# FSS_FSAS_0_FSS_FSAS_GENREGS_0FC10000h register map
Vendor: Texas Instruments
Peripheral module from a debugger description file (folder am62D).
Registers are 32-bit, access not given, reset 0x0 unless marked. A register's access mark holds for its fields unless they carry their own. Offsets are as the file gives them; lines under a group give offsets from that group; [hi:lo] are bit positions; {n}, {i} and the like mark numbered series; 'fields as' and 'values as' point back to an identical list; <NAME> marks a mode.

## fss_fsas_genregs
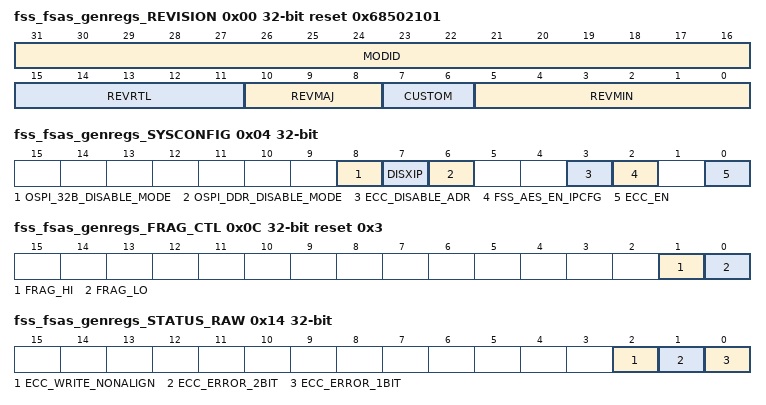
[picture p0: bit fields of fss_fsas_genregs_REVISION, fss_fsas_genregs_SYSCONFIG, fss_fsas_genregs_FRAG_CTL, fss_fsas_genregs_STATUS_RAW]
0x00 fss_fsas_genregs_REVISION ro reset 0x68502101 — IP Revision Identifier (X.Y.R) Used by software to track features, bugs, and compatibility
  [31:16] MODID — Module ID field Reset Source: vbus_mod_g_rst_n
  [15:11] REVRTL — RTL revision. Will vary depending on release. Reset Source: vbus_mod_g_rst_n
  [10:8] REVMAJ — Major revision Reset Source: vbus_mod_g_rst_n
  [7:6] CUSTOM — Custom Reset Source: vbus_mod_g_rst_n
  [5:0] REVMIN — Minor revision Reset Source: vbus_mod_g_rst_n
0x04 fss_fsas_genregs_SYSCONFIG access per field — Controls various parameters of the cotroller state.
  [8] OSPI_32B_DISABLE_MODE rw — 0 OSPI 32bit mode enabled. 1 OSPI 32bit mode disabled Reset Source: vbus_mod_g_rst_n
  [7] DISXIP rw — 0 XIP Prefetch Enabled. 1 XIP prefetch disabled Reset Source: vbus_mod_g_rst_n
  [6] OSPI_DDR_DISABLE_MODE rw — 0 OSPI DDR mode enabled. 1 OSPI DDR mode disabled Reset Source: vbus_mod_g_rst_n
  [3] ECC_DISABLE_ADR rw — 0 Block address within ECC calculation, 1 Block address not within ECC calculation Reset Source: vbus_mod_g_rst_n
  [2] FSS_AES_EN_IPCFG ro — 1 select security, 0 disable security Reset Source: vbus_mod_g_rst_n
  [0] ECC_EN rw — 0 ECC disabled. 1 ECC enabled Reset Source: vbus_mod_g_rst_n
0x08 fss_fsas_genregs_FRAG_ADR rw — This FRAG_ADR is the address of a request that frag_hi or frag_lo boundary occurs
  [31:0] FRAG_ADDR — This address is used to determine the boundary of frag_hi and flag_lo Reset Source: vbus_mod_g_rst_n
0x0C fss_fsas_genregs_FRAG_CTL rw reset 0x3 — The FRAG_CTL determins which frag region is fragmented
  [1] FRAG_HI — When set any address greater than or equal to frag_addr will be fragmented to 16 bits Reset Source: vbus_mod_g_rst_n
  [0] FRAG_LO — When set any address less than frag_addr will be fragmented to 16 bits Reset Source: vbus_mod_g_rst_n
0x10 fss_fsas_genregs_IRQ reset not defined
0x10 fss_fsas_genregs_EOI rw — The End of Interrupt (EOI) MISC Register allows the CPU to acknowledge completion of an interrupt by writing to the EOI for MISC interrupt sources. An eoi_write signal will be generated and another interrupt will be triggered if interrupt sources remain. This register will be reset one cycle after it has been written to.
  [0] EOI_VECTOR — Write with bit position of targeted interrupt. (E.g. Ext FSS ECC is bit 0). Upon write, level interrupt will clear and if un-serviced will issue another pulse interrupt Reset Source: vbus_mod_g_rst_n
0x14 fss_fsas_genregs_STATUS_RAW — The IRQ_STATUS_RAW register allows the interrupt sources to be manually set when writing a 1 to a specific bit. Write 0: No action Write 1: Set event Read 0: No event pending Read 1: Event pending
  [2] ECC_WRITE_NONALIGN — Write is not aligned to 32B boundary or not a multiple of 32B Reset Source: vbus_mod_g_rst_n (access R/W1TS)
  [1] ECC_ERROR_2BIT — ECC error on 2 bits. Not correctable Reset Source: vbus_mod_g_rst_n (access R/W1TS)
  [0] ECC_ERROR_1BIT — ECC error on 1 bits. correctable Reset Source: vbus_mod_g_rst_n (access R/W1TS)
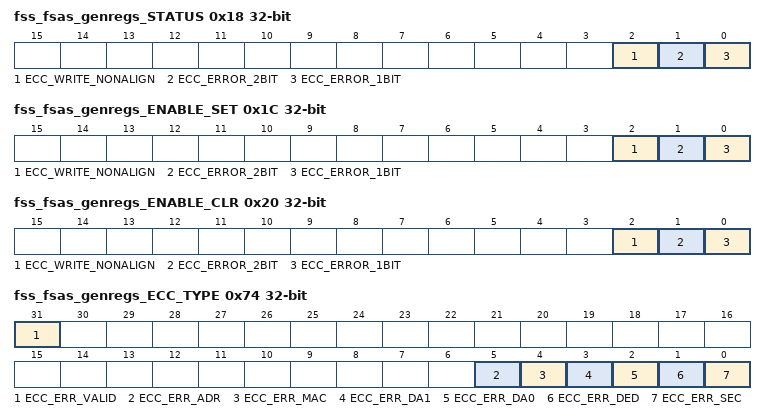
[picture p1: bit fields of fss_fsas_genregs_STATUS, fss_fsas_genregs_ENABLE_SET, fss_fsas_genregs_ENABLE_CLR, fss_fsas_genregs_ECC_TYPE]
0x18 fss_fsas_genregs_STATUS — The IRQ_STATUS register allows the interrupt sources to be manually cleared when writing a 1 to a specific bit. Write 0: No action Write 1: Clear event Read 0: No event pending Read 1: Event pending
  [2] ECC_WRITE_NONALIGN — Write is not aligned to 32B boundary or not a multiple of 32B Reset Source: vbus_mod_g_rst_n (access R/W1TC)
  [1] ECC_ERROR_2BIT — ECC error on 2 bits. Not correctable Reset Source: vbus_mod_g_rst_n (access R/W1TC)
  [0] ECC_ERROR_1BIT — ECC error on 1 bits. correctable Reset Source: vbus_mod_g_rst_n (access R/W1TC)
0x1C fss_fsas_genregs_ENABLE_SET — The IRQ_ENABLE_SET register allows the interrupt sources to be manually enabled when writing a 1 to a specific bit. Write 0: No action Write 1: Enable event Read 0: Event is disabled Read 1: Event is enabled
  fields as fss_fsas_genregs_STATUS_RAW
0x20 fss_fsas_genregs_ENABLE_CLR — The IRQ_ENABLE_CLR register allows the interrupt sources to be manually disabled when writing a 1 to a specific bit. Write 0: No action Write 1: Disable event Read 0: Event is disabled Read 1: Event is enabled
  fields as fss_fsas_genregs_STATUS
0x30 fss_fsas_genregs_ECC_REGCTRL_ECC_RGSTRT_j rw — This defines the start of the ECC region in 4KBytes steps.
  [19:0] R_START — This defines the start of the ECC region in 4KBytes steps. Address start = {start[19:0], 0x000}0x0 means the start is 0x0000_0000 0x1 means the start is 0x0000_10000xA means the start is 0x0000_A000Note the offset + size should be <= 4GBytes, wrap around is not supported. Reset Source: vbus_mod_g_rst_n
0x34 fss_fsas_genregs_ECC_REGCTRL_ECC_RGSIZ_j rw — This defines the size of the ECC region in 4KBytes steps.
  [19:0] R_SIZE — This defines the size of the ECC region in 4KBytes steps0x0 means the size is zero and disabled 0x1 means the size is 4KBytes0xA means the size is 40KBytes0xF_FFFF means the size is 4GBytesNote the offset + size should be <= 4GBytes, wrap around is not supported. Reset Source: vbus_mod_g_rst_n
0x70 fss_fsas_genregs_ERR reset not defined
0x70 fss_fsas_genregs_ECC_BLOCK_ADR ro — The ERR_ECC_BLOCK_ADR register holds the current top of stack ECC error block address, this is only valid when the ecc_err_valid is set
  [31:5] ECC_ERROR_BLOCK_ADDR — ECC 32 byte aligned block address Reset Source: vbus_mod_g_rst_n
0x74 fss_fsas_genregs_ECC_TYPE — The ERR_ECC_TYPE register holds the current top of stack ECC error info, this is only valid when the ecc_err_valid is set
  [31] ECC_ERR_VALID — When set indicates that there is valid ECC error information available, Writing a one to this register will pop the top of the stack Reset Source: vbus_mod_g_rst_n (access R/W1TC)
  [5] ECC_ERR_ADR ro — When set indicates that there was a single error detected within the address field Reset Source: vbus_mod_g_rst_n
  [4] ECC_ERR_MAC ro — When set indicates that there was a single error detected within the MAC field Reset Source: vbus_mod_g_rst_n
  [3] ECC_ERR_DA1 ro — When set indicates that there was a single error detected within the High Data word Reset Source: vbus_mod_g_rst_n
  [2] ECC_ERR_DA0 ro — When set indicates that there was a single error detected within the Low Data word Reset Source: vbus_mod_g_rst_n
  [1] ECC_ERR_DED ro — When set indicates that there was a double error detected for the block Reset Source: vbus_mod_g_rst_n
  [0] ECC_ERR_SEC ro — hen set indicates that there was a single error detected for the block Reset Source: vbus_mod_g_rst_n
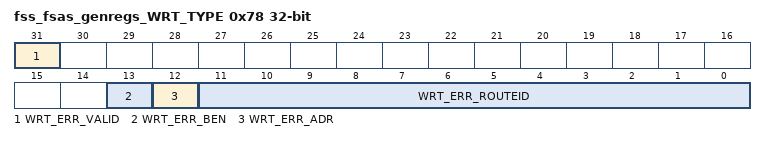
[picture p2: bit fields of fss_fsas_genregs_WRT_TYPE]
0x78 fss_fsas_genregs_WRT_TYPE — The ERR_WRT_TYPE register holds the current top of stack write error info. this is only valid when the wrt_err_valid is set
  [31] WRT_ERR_VALID — When set indicates that there is valid write error information available, Writing a one to this register will pop the top of the stack Reset Source: vbus_mod_g_rst_n (access R/W1TC)
  [13] WRT_ERR_BEN ro — When set indicates that there was a write error due to a non-contiguous byte enables Reset Source: vbus_mod_g_rst_n
  [12] WRT_ERR_ADR ro — When set indicates that there was a write error due to a non-aligned address Reset Source: vbus_mod_g_rst_n
  [11:0] WRT_ERR_ROUTEID ro — Indicates the Route ID for the Master that caused the write error Reset Source: vbus_mod_g_rst_n
